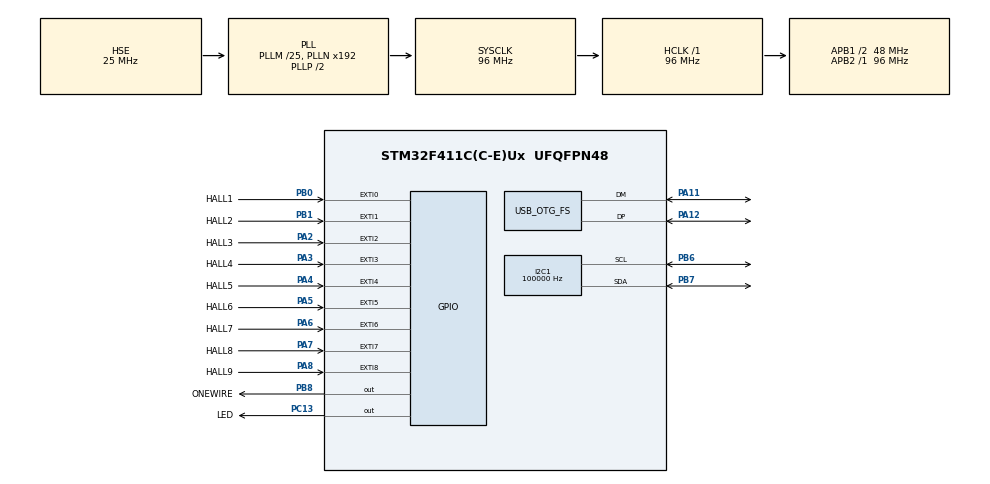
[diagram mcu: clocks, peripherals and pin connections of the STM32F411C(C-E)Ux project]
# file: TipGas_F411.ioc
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I2C1.I2C_Speed_Mode=I2C_Standard
I2C1.ClockSpeed=100000
Mcu.Family=STM32F4
Mcu.Name=STM32F411C(C-E)Ux
Mcu.Package=UFQFPN48
NVIC.EXTI0_IRQn=true\:2\:0\:false\:false\:true\:true\:true\:true
NVIC.EXTI1_IRQn=true\:2\:0\:false\:false\:true\:true\:true\:true
NVIC.EXTI2_IRQn=true\:2\:0\:false\:false\:true\:true\:true\:true
NVIC.EXTI3_IRQn=true\:2\:0\:false\:false\:true\:true\:true\:true
NVIC.EXTI4_IRQn=true\:2\:0\:false\:false\:true\:true\:true\:true
NVIC.EXTI9_5_IRQn=true\:2\:0\:false\:false\:true\:true\:true\:true
NVIC.OTG_FS_IRQn=true\:0\:0\:false\:false\:true\:false\:true\:true
NVIC.PriorityGroup=NVIC_PRIORITYGROUP_4
PA11.Mode=Device_Only
PA11.Signal=USB_OTG_FS_DM
PA12.Mode=Device_Only
PA12.Signal=USB_OTG_FS_DP
PA13.Mode=Serial_Wire
PA13.Signal=SYS_JTMS-SWDIO
PA14.Mode=Serial_Wire
PA14.Signal=SYS_JTCK-SWCLK
PA2.GPIO_Label=HALL3
PA2.GPIO_ModeDefaultEXTI=GPIO_MODE_IT_RISING_FALLING
PA2.GPIO_PuPd=GPIO_PULLUP
PA2.Signal=GPXTI2
PA3.GPIO_Label=HALL4
PA3.GPIO_ModeDefaultEXTI=GPIO_MODE_IT_RISING_FALLING
PA3.GPIO_PuPd=GPIO_PULLUP
PA3.Signal=GPXTI3
PA4.GPIO_Label=HALL5
PA4.GPIO_ModeDefaultEXTI=GPIO_MODE_IT_RISING_FALLING
PA4.GPIO_PuPd=GPIO_PULLUP
PA4.Signal=GPXTI4
PA5.GPIO_Label=HALL6
PA5.GPIO_ModeDefaultEXTI=GPIO_MODE_IT_RISING_FALLING
PA5.GPIO_PuPd=GPIO_PULLUP
PA5.Signal=GPXTI5
PA6.GPIO_Label=HALL7
PA6.GPIO_ModeDefaultEXTI=GPIO_MODE_IT_RISING_FALLING
PA6.GPIO_PuPd=GPIO_PULLUP
PA6.Signal=GPXTI6
PA7.GPIO_Label=HALL8
PA7.GPIO_ModeDefaultEXTI=GPIO_MODE_IT_RISING_FALLING
PA7.GPIO_PuPd=GPIO_PULLUP
PA7.Signal=GPXTI7
PA8.GPIO_Label=HALL9
PA8.GPIO_ModeDefaultEXTI=GPIO_MODE_IT_RISING_FALLING
PA8.GPIO_PuPd=GPIO_PULLUP
PA8.Signal=GPXTI8
PB0.GPIO_Label=HALL1
PB0.GPIO_ModeDefaultEXTI=GPIO_MODE_IT_RISING_FALLING
PB0.GPIO_PuPd=GPIO_PULLUP
PB0.Signal=GPXTI0
PB1.GPIO_Label=HALL2
PB1.GPIO_ModeDefaultEXTI=GPIO_MODE_IT_RISING_FALLING
PB1.GPIO_PuPd=GPIO_PULLUP
PB1.Signal=GPXTI1
PB6.GPIO_PuPd=GPIO_PULLUP
PB6.Mode=I2C
PB6.Signal=I2C1_SCL
PB7.GPIO_PuPd=GPIO_PULLUP
PB7.Mode=I2C
PB7.Signal=I2C1_SDA
PB8.GPIO_Label=ONEWIRE
PB8.GPIO_ModeDefaultOutputPP=GPIO_MODE_OUTPUT_OD
PB8.GPIO_PuPd=GPIO_PULLUP
PB8.GPIO_Speed=GPIO_SPEED_FREQ_HIGH
PB8.PinState=GPIO_PIN_SET
PB8.Signal=GPIO_Output
PC13-ANTI_TAMP.GPIO_Label=LED
PC13-ANTI_TAMP.PinState=GPIO_PIN_SET
PC13-ANTI_TAMP.Signal=GPIO_Output
PH0\ -\ OSC_IN.Mode=HSE-External-Oscillator
PH0\ -\ OSC_IN.Signal=RCC_OSC_IN
PH1\ -\ OSC_OUT.Mode=HSE-External-Oscillator
PH1\ -\ OSC_OUT.Signal=RCC_OSC_OUT
ProjectManager.HeapSize=0x200
ProjectManager.StackSize=0x800
ProjectManager.TargetToolchain=STM32CubeIDE
RCC.AHBFreq_Value=96000000
RCC.APB1CLKDivider=RCC_HCLK_DIV2
RCC.APB1Freq_Value=48000000
RCC.APB1TimFreq_Value=96000000
RCC.APB2Freq_Value=96000000
RCC.APB2TimFreq_Value=96000000
RCC.CortexFreq_Value=96000000
RCC.HCLKFreq_Value=96000000
RCC.HSE_VALUE=25000000
RCC.HSI_VALUE=16000000
RCC.PLLM=25
RCC.PLLN=192
RCC.PLLQ=4
RCC.PLLSourceVirtual=RCC_PLLSOURCE_HSE
RCC.SYSCLKFreq_VALUE=96000000
RCC.SYSCLKSource=RCC_SYSCLKSOURCE_PLLCLK
RCC.USBFreq_Value=48000000
RCC.VCOOutputFreq_Value=192000000
USB_DEVICE.CLASS_NAME_FS=CDC
USB_DEVICE.MANUFACTURER_STRING=UTFPR
USB_DEVICE.PRODUCT_STRING_CDC_FS=TipGas 9-channel gas meter
USB_DEVICE.VirtualMode=Cdc
USB_DEVICE.VirtualModeFS=Cdc_FS
USB_OTG_FS.VirtualMode=Device_Only
VP_USB_DEVICE_VS_USB_DEVICE_CDC_FS.Mode=CDC_FS
board=custom

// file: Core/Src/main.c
/* USER CODE BEGIN Header */
/**
  ******************************************************************************
  * @file           : main.c
  * @brief          : TipGas - medidor de gas tipping-bucket, 9 canais - Black Pill STM32F411
  ******************************************************************************
  * Clock: HSE 25 MHz -> PLL -> SYSCLK 96 MHz, USB 48 MHz
  * Perifericos: GPIO/EXTI (9 sensores Hall), I2C1 (BME280 opcional), USB OTG FS (CDC)
  ******************************************************************************
  */
/* USER CODE END Header */
#include "main.h"
#include "usb_device.h"

/* USER CODE BEGIN Includes */
#include "app_flowmeter.h"
/* USER CODE END Includes */

I2C_HandleTypeDef hi2c1;

void SystemClock_Config(void);
static void MX_GPIO_Init(void);
static void MX_I2C1_Init(void);

int main(void)
{

  /* MCU Configuration--------------------------------------------------------*/

  /* Reset of all peripherals, Initializes the Flash interface and the Systick. */
  HAL_Init();

  /* Configure the system clock */
  SystemClock_Config();

  /* Initialize all configured peripherals */
  MX_GPIO_Init();
  MX_I2C1_Init();
  MX_USB_DEVICE_Init();
  /* USER CODE BEGIN 2 */
  FM_Init();
  /* USER CODE END 2 */

  /* Infinite loop */
  while (1)
  {

    /* USER CODE BEGIN 3 */
    FM_Process();
  }
  /* USER CODE END 3 */
}

void SystemClock_Config(void)
{
  RCC_OscInitTypeDef RCC_OscInitStruct = {0};
  RCC_ClkInitTypeDef RCC_ClkInitStruct = {0};

  /** Configure the main internal regulator output voltage
  */
  __HAL_RCC_PWR_CLK_ENABLE();
  __HAL_PWR_VOLTAGESCALING_CONFIG(PWR_REGULATOR_VOLTAGE_SCALE1);

  /** Initializes the RCC Oscillators according to the specified parameters
  * in the RCC_OscInitTypeDef structure.
  */
  RCC_OscInitStruct.OscillatorType = RCC_OSCILLATORTYPE_HSE;
  RCC_OscInitStruct.HSEState = RCC_HSE_ON;
  RCC_OscInitStruct.PLL.PLLState = RCC_PLL_ON;
  RCC_OscInitStruct.PLL.PLLSource = RCC_PLLSOURCE_HSE;
  RCC_OscInitStruct.PLL.PLLM = 25;
  RCC_OscInitStruct.PLL.PLLN = 192;
  RCC_OscInitStruct.PLL.PLLP = RCC_PLLP_DIV2;
  RCC_OscInitStruct.PLL.PLLQ = 4;
  if (HAL_RCC_OscConfig(&RCC_OscInitStruct) != HAL_OK)
  {
    Error_Handler();
  }

  /** Initializes the CPU, AHB and APB buses clocks
  */
  RCC_ClkInitStruct.ClockType = RCC_CLOCKTYPE_HCLK|RCC_CLOCKTYPE_SYSCLK
                              |RCC_CLOCKTYPE_PCLK1|RCC_CLOCKTYPE_PCLK2;
  RCC_ClkInitStruct.SYSCLKSource = RCC_SYSCLKSOURCE_PLLCLK;
  RCC_ClkInitStruct.AHBCLKDivider = RCC_SYSCLK_DIV1;
  RCC_ClkInitStruct.APB1CLKDivider = RCC_HCLK_DIV2;
  RCC_ClkInitStruct.APB2CLKDivider = RCC_HCLK_DIV1;

  if (HAL_RCC_ClockConfig(&RCC_ClkInitStruct, FLASH_LATENCY_3) != HAL_OK)
  {
    Error_Handler();
  }
}

static void MX_I2C1_Init(void)
{

  hi2c1.Instance = I2C1;
  hi2c1.Init.ClockSpeed = 100000;
  hi2c1.Init.DutyCycle = I2C_DUTYCYCLE_2;
  hi2c1.Init.OwnAddress1 = 0;
  hi2c1.Init.AddressingMode = I2C_ADDRESSINGMODE_7BIT;
  hi2c1.Init.DualAddressMode = I2C_DUALADDRESS_DISABLE;
  hi2c1.Init.OwnAddress2 = 0;
  hi2c1.Init.GeneralCallMode = I2C_GENERALCALL_DISABLE;
  hi2c1.Init.NoStretchMode = I2C_NOSTRETCH_DISABLE;
  if (HAL_I2C_Init(&hi2c1) != HAL_OK)
  {
    Error_Handler();
  }

}

static void MX_GPIO_Init(void)
{
  GPIO_InitTypeDef GPIO_InitStruct = {0};

  /* GPIO Ports Clock Enable */
  __HAL_RCC_GPIOC_CLK_ENABLE();
  __HAL_RCC_GPIOH_CLK_ENABLE();
  __HAL_RCC_GPIOA_CLK_ENABLE();
  __HAL_RCC_GPIOB_CLK_ENABLE();

  /*Configure GPIO pin Output Level */
  HAL_GPIO_WritePin(LED_GPIO_Port, LED_Pin, GPIO_PIN_SET);

  /*Configure GPIO pin Output Level */
  HAL_GPIO_WritePin(ONEWIRE_GPIO_Port, ONEWIRE_Pin, GPIO_PIN_SET);

  /*Configure GPIO pin : LED_Pin */
  GPIO_InitStruct.Pin = LED_Pin;
  GPIO_InitStruct.Mode = GPIO_MODE_OUTPUT_PP;
  GPIO_InitStruct.Pull = GPIO_NOPULL;
  GPIO_InitStruct.Speed = GPIO_SPEED_FREQ_LOW;
  HAL_GPIO_Init(LED_GPIO_Port, &GPIO_InitStruct);

  /*Configure GPIO pins : HALL3_Pin HALL4_Pin HALL5_Pin HALL6_Pin
                           HALL7_Pin HALL8_Pin HALL9_Pin */
  GPIO_InitStruct.Pin = HALL3_Pin|HALL4_Pin|HALL5_Pin|HALL6_Pin
                          |HALL7_Pin|HALL8_Pin|HALL9_Pin;
  GPIO_InitStruct.Mode = GPIO_MODE_IT_RISING_FALLING;
  GPIO_InitStruct.Pull = GPIO_PULLUP;
  HAL_GPIO_Init(GPIOA, &GPIO_InitStruct);

  /*Configure GPIO pin : ONEWIRE_Pin (1-Wire dos DS18B20: open-drain, pull-up externo de 4,7 kOhm) */
  GPIO_InitStruct.Pin = ONEWIRE_Pin;
  GPIO_InitStruct.Mode = GPIO_MODE_OUTPUT_OD;
  GPIO_InitStruct.Pull = GPIO_PULLUP;
  GPIO_InitStruct.Speed = GPIO_SPEED_FREQ_HIGH;
  HAL_GPIO_Init(ONEWIRE_GPIO_Port, &GPIO_InitStruct);

  /*Configure GPIO pins : HALL1_Pin HALL2_Pin */
  GPIO_InitStruct.Pin = HALL1_Pin|HALL2_Pin;
  GPIO_InitStruct.Mode = GPIO_MODE_IT_RISING_FALLING;
  GPIO_InitStruct.Pull = GPIO_PULLUP;
  HAL_GPIO_Init(GPIOB, &GPIO_InitStruct);

  /* EXTI interrupt init*/
  HAL_NVIC_SetPriority(EXTI0_IRQn, 2, 0);
  HAL_NVIC_EnableIRQ(EXTI0_IRQn);

  HAL_NVIC_SetPriority(EXTI1_IRQn, 2, 0);
  HAL_NVIC_EnableIRQ(EXTI1_IRQn);

  HAL_NVIC_SetPriority(EXTI2_IRQn, 2, 0);
  HAL_NVIC_EnableIRQ(EXTI2_IRQn);

  HAL_NVIC_SetPriority(EXTI3_IRQn, 2, 0);
  HAL_NVIC_EnableIRQ(EXTI3_IRQn);

  HAL_NVIC_SetPriority(EXTI4_IRQn, 2, 0);
  HAL_NVIC_EnableIRQ(EXTI4_IRQn);

  HAL_NVIC_SetPriority(EXTI9_5_IRQn, 2, 0);
  HAL_NVIC_EnableIRQ(EXTI9_5_IRQn);

}

/* USER CODE BEGIN 4 */
void HAL_GPIO_EXTI_Callback(uint16_t GPIO_Pin)
{
  FM_OnExti(GPIO_Pin);
}
/* USER CODE END 4 */

void Error_Handler(void)
{
  __disable_irq();
  while (1)
  {
  }
}

#ifdef  USE_FULL_ASSERT
void assert_failed(uint8_t *file, uint32_t line)
{
  /* USER CODE BEGIN 6 */
  (void)file; (void)line;
  /* USER CODE END 6 */
}
#endif /* USE_FULL_ASSERT */
